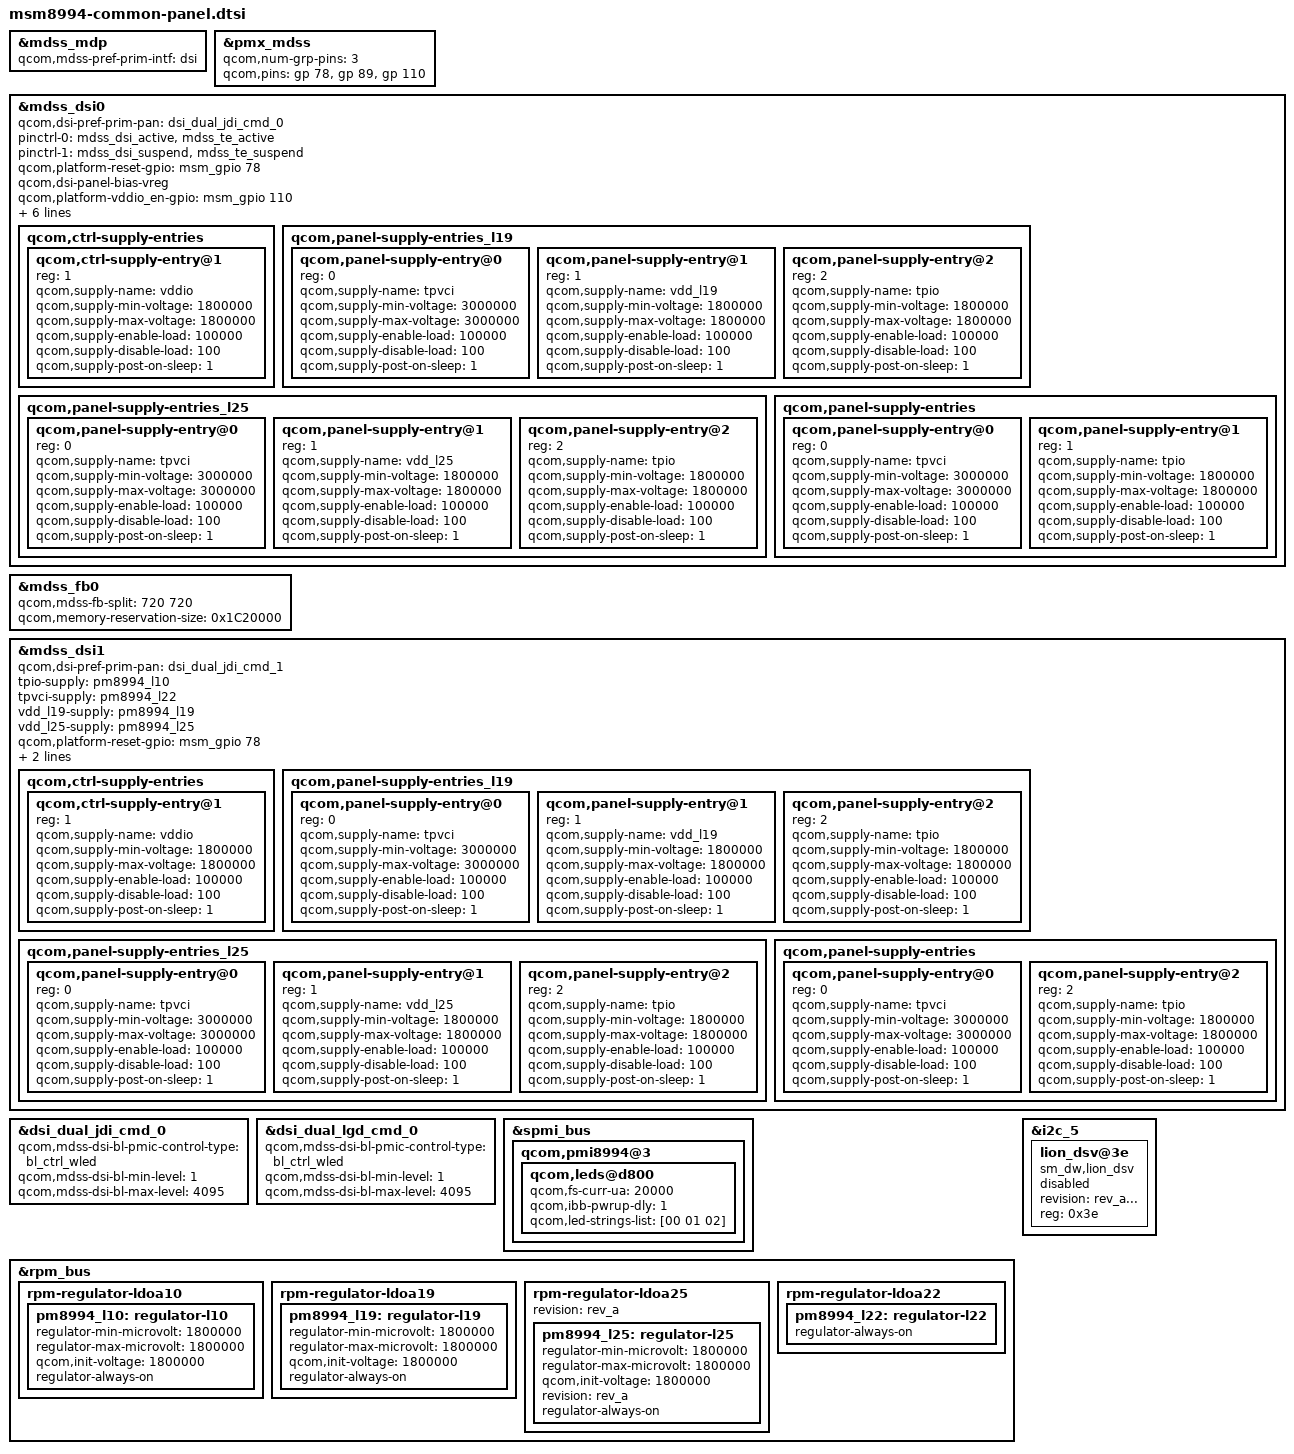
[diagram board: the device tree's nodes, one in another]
/* Copyright (c) 2014, The Linux Foundation. All rights reserved.
 *
 * This program is free software; you can redistribute it and/or modify
 * it under the terms of the GNU General Public License version 2 and
 * only version 2 as published by the Free Software Foundation.
 *
 * This program is distributed in the hope that it will be useful,
 * but WITHOUT ANY WARRANTY; without even the implied warranty of
 * MERCHANTABILITY or FITNESS FOR A PARTICULAR PURPOSE.  See the
 * GNU General Public License for more details.
 */


//copy from msm8994-cdp.dtsi and modify.

#include "dsi-panel-jdi-nt36850-dualmipi0-qhd-cmd.dtsi"
#include "dsi-panel-jdi-nt36850-dualmipi1-qhd-cmd.dtsi"
//#include "dsi-panel-jdi-nt36850-dualmipi0-qhd-video.dtsi"
//#include "dsi-panel-jdi-nt36850-dualmipi1-qhd-video.dtsi"
#include "dsi-panel-lgd-r69007-dualmipi0-qhd-cmd.dtsi"
#include "dsi-panel-lgd-r69007-dualmipi1-qhd-cmd.dtsi"

&mdss_mdp {
	qcom,mdss-pref-prim-intf = "dsi";
	/delete-property/ qcom,mdss-has-source-split;
};

&pmx_mdss {
	qcom,num-grp-pins = <3>;
	qcom,pins = <&gp 78>, <&gp 89>, <&gp 110>;
};

&mdss_dsi0 {
	qcom,dsi-pref-prim-pan = <&dsi_dual_jdi_cmd_0>;
	pinctrl-names = "mdss_default", "mdss_sleep";

	/* pinctrl-0 = <&mdss_dsi_active>; */
	/* pinctrl-1 = <&mdss_dsi_suspend>; */
	/* Add TE pin control status on the PINCTRL structure */
	pinctrl-0 = <&mdss_dsi_active &mdss_te_active>;
	pinctrl-1 = <&mdss_dsi_suspend &mdss_te_suspend>;

	qcom,platform-reset-gpio = <&msm_gpio 78 0>;
	qcom,dsi-panel-bias-vreg;
	qcom,platform-vddio_en-gpio = <&msm_gpio 110 0>;
	qcom,platform-avdd-gpio = <&msm_gpio 89 0>;

	lge,vdd_ldo = < // 1:LDO19 2:LDO25 3:NONE
		1 1  // rev_0 = 1;  rev_a = 1
		3 3  // rev_b = 3;  rev_c = 3
		3 3  // rev_d = 3;  rev_e = 3
		3 3  // rev_f = 3;  rev_g = 3
		3 3  // rev_10 = 3; rev_11 = 3
		3    // rev_12 = 3;
		>;

	tpio-supply = <&pm8994_l10>;
	tpvci-supply =  <&pm8994_l22>;
	vdd_l19-supply = <&pm8994_l19>;
	vdd_l25-supply = <&pm8994_l25>;

	qcom,ctrl-supply-entries {
		qcom,ctrl-supply-entry@1 { //vddio-supply = <&pm8994_l12>;
			reg = <1>;
			qcom,supply-name = "vddio";
			qcom,supply-min-voltage = <1800000>;
			qcom,supply-max-voltage = <1800000>;
			qcom,supply-enable-load = <100000>;
			qcom,supply-disable-load = <100>;
			qcom,supply-post-on-sleep = <1>;
		};
	};

	qcom,panel-supply-entries_l19 {
		#address-cells = <1>;
		#size-cells = <0>;

		qcom,panel-supply-entry@0 {
			reg = <0>;
			qcom,supply-name = "tpvci";
			qcom,supply-min-voltage = <3000000>;
			qcom,supply-max-voltage = <3000000>;
			qcom,supply-enable-load = <100000>;
			qcom,supply-disable-load = <100>;
			qcom,supply-post-on-sleep = <1>;
		};

		qcom,panel-supply-entry@1 {
			reg = <1>;
			qcom,supply-name = "vdd_l19";
			qcom,supply-min-voltage = <1800000>;
			qcom,supply-max-voltage = <1800000>;
			qcom,supply-enable-load = <100000>;
			qcom,supply-disable-load = <100>;
			qcom,supply-post-on-sleep = <1>;
		};

		qcom,panel-supply-entry@2 {
			reg = <2>;
			qcom,supply-name = "tpio";
			qcom,supply-min-voltage = <1800000>;
			qcom,supply-max-voltage = <1800000>;
			qcom,supply-enable-load = <100000>;
			qcom,supply-disable-load = <100>;
			qcom,supply-post-on-sleep = <1>;
		};
	};

	qcom,panel-supply-entries_l25 {
		#address-cells = <1>;
		#size-cells = <0>;

		qcom,panel-supply-entry@0 {
			reg = <0>;
			qcom,supply-name = "tpvci";
			qcom,supply-min-voltage = <3000000>;
			qcom,supply-max-voltage = <3000000>;
			qcom,supply-enable-load = <100000>;
			qcom,supply-disable-load = <100>;
			qcom,supply-post-on-sleep = <1>;
		};

		qcom,panel-supply-entry@1 {
			reg = <1>;
			qcom,supply-name = "vdd_l25";
			qcom,supply-min-voltage = <1800000>;
			qcom,supply-max-voltage = <1800000>;
			qcom,supply-enable-load = <100000>;
			qcom,supply-disable-load = <100>;
			qcom,supply-post-on-sleep = <1>;
		};

		qcom,panel-supply-entry@2 {
			reg = <2>;
			qcom,supply-name = "tpio";
			qcom,supply-min-voltage = <1800000>;
			qcom,supply-max-voltage = <1800000>;
			qcom,supply-enable-load = <100000>;
			qcom,supply-disable-load = <100>;
			qcom,supply-post-on-sleep = <1>;
		};
	};

	qcom,panel-supply-entries {
		#address-cells = <1>;
		#size-cells = <0>;

		qcom,panel-supply-entry@0 {
			reg = <0>;
			qcom,supply-name = "tpvci";
			qcom,supply-min-voltage = <3000000>;
			qcom,supply-max-voltage = <3000000>;
			qcom,supply-enable-load = <100000>;
			qcom,supply-disable-load = <100>;
			qcom,supply-post-on-sleep = <1>;
		};

		qcom,panel-supply-entry@1 {
			reg = <1>;
			qcom,supply-name = "tpio";
			qcom,supply-min-voltage = <1800000>;
			qcom,supply-max-voltage = <1800000>;
			qcom,supply-enable-load = <100000>;
			qcom,supply-disable-load = <100>;
			qcom,supply-post-on-sleep = <1>;
		};
	};
};

&mdss_fb0 {
	qcom,mdss-fb-split = <720 720>;
	qcom,memory-reservation-size = <0x1C20000>;
};

&mdss_dsi1 {
	qcom,dsi-pref-prim-pan = <&dsi_dual_jdi_cmd_1>;

	tpio-supply = <&pm8994_l10>;
	tpvci-supply =  <&pm8994_l22>;
	vdd_l19-supply = <&pm8994_l19>;
	vdd_l25-supply = <&pm8994_l25>;

	qcom,platform-reset-gpio = <&msm_gpio 78 0>;
	lge,reset-low-hold = <10>;

	lge,vdd_ldo = < // 1:LDO19 2:LDO25 3:NONE
		1 1  // rev_0 = 1;  rev_a = 1
		3 3  // rev_b = 3;  rev_c = 3
		3 3  // rev_d = 3;  rev_e = 3
		3 3  // rev_f = 3;  rev_g = 3
		3 3  // rev_10 = 3; rev_11 = 3
		3    // rev_12 = 3;
		>;

	qcom,ctrl-supply-entries {
		qcom,ctrl-supply-entry@1 { //vddio-supply = <&pm8994_l12>;
			reg = <1>;
			qcom,supply-name = "vddio";
			qcom,supply-min-voltage = <1800000>;
			qcom,supply-max-voltage = <1800000>;
			qcom,supply-enable-load = <100000>;
			qcom,supply-disable-load = <100>;
			qcom,supply-post-on-sleep = <1>;
		};
	};

	qcom,panel-supply-entries_l19 {
		#address-cells = <1>;
		#size-cells = <0>;

		qcom,panel-supply-entry@0 {
			reg = <0>;
			qcom,supply-name = "tpvci";
			qcom,supply-min-voltage = <3000000>;
			qcom,supply-max-voltage = <3000000>;
			qcom,supply-enable-load = <100000>;
			qcom,supply-disable-load = <100>;
			qcom,supply-post-on-sleep = <1>;
		};

		qcom,panel-supply-entry@1 {
			reg = <1>;
			qcom,supply-name = "vdd_l19";
			qcom,supply-min-voltage = <1800000>;
			qcom,supply-max-voltage = <1800000>;
			qcom,supply-enable-load = <100000>;
			qcom,supply-disable-load = <100>;
			qcom,supply-post-on-sleep = <1>;
		};

		qcom,panel-supply-entry@2 {
			reg = <2>;
			qcom,supply-name = "tpio";
			qcom,supply-min-voltage = <1800000>;
			qcom,supply-max-voltage = <1800000>;
			qcom,supply-enable-load = <100000>;
			qcom,supply-disable-load = <100>;
			qcom,supply-post-on-sleep = <1>;
		};
	};

	qcom,panel-supply-entries_l25 {
		#address-cells = <1>;
		#size-cells = <0>;

		qcom,panel-supply-entry@0 {
			reg = <0>;
			qcom,supply-name = "tpvci";
			qcom,supply-min-voltage = <3000000>;
			qcom,supply-max-voltage = <3000000>;
			qcom,supply-enable-load = <100000>;
			qcom,supply-disable-load = <100>;
			qcom,supply-post-on-sleep = <1>;
		};

		qcom,panel-supply-entry@1 {
			reg = <1>;
			qcom,supply-name = "vdd_l25";
			qcom,supply-min-voltage = <1800000>;
			qcom,supply-max-voltage = <1800000>;
			qcom,supply-enable-load = <100000>;
			qcom,supply-disable-load = <100>;
			qcom,supply-post-on-sleep = <1>;
		};

		qcom,panel-supply-entry@2 {
			reg = <2>;
			qcom,supply-name = "tpio";
			qcom,supply-min-voltage = <1800000>;
			qcom,supply-max-voltage = <1800000>;
			qcom,supply-enable-load = <100000>;
			qcom,supply-disable-load = <100>;
			qcom,supply-post-on-sleep = <1>;
		};
	};

	qcom,panel-supply-entries {
		#address-cells = <1>;
		#size-cells = <0>;

		qcom,panel-supply-entry@0 {
			reg = <0>;
			qcom,supply-name = "tpvci";
			qcom,supply-min-voltage = <3000000>;
			qcom,supply-max-voltage = <3000000>;
			qcom,supply-enable-load = <100000>;
			qcom,supply-disable-load = <100>;
			qcom,supply-post-on-sleep = <1>;
		};

		qcom,panel-supply-entry@2 {
			reg = <2>;
			qcom,supply-name = "tpio";
			qcom,supply-min-voltage = <1800000>;
			qcom,supply-max-voltage = <1800000>;
			qcom,supply-enable-load = <100000>;
			qcom,supply-disable-load = <100>;
			qcom,supply-post-on-sleep = <1>;
		};
	};
};

&dsi_dual_jdi_cmd_0{
	qcom,mdss-dsi-bl-pmic-control-type = "bl_ctrl_wled";
	qcom,mdss-dsi-bl-min-level = <1>;
	qcom,mdss-dsi-bl-max-level = <4095>;
};

&dsi_dual_lgd_cmd_0{
	qcom,mdss-dsi-bl-pmic-control-type = "bl_ctrl_wled";
	qcom,mdss-dsi-bl-min-level = <1>;
	qcom,mdss-dsi-bl-max-level = <4095>;
};

&spmi_bus {
	qcom,pmi8994@3 {
		qcom,leds@d800 {
			qcom,fs-curr-ua = <20000>;
			qcom,ibb-pwrup-dly = <1>;
			qcom,led-strings-list = [00 01 02];
		};
	};
};

/* RPM controlled regulators: */

&rpm_bus {
	rpm-regulator-ldoa10 {
		status = "okay";
		pm8994_l10: regulator-l10 {
			regulator-min-microvolt = <1800000>;
			regulator-max-microvolt = <1800000>;
			qcom,init-voltage = <1800000>;
			status = "okay";
			regulator-always-on;
		};

	};
	rpm-regulator-ldoa19 {
		status = "okay";
		pm8994_l19: regulator-l19 {
			regulator-min-microvolt = <1800000>;
			regulator-max-microvolt = <1800000>;
			qcom,init-voltage = <1800000>;
			status = "okay";
			regulator-always-on;
		};
	};
	rpm-regulator-ldoa25 {
		status = "okay";
		revision = "rev_a";
		pm8994_l25: regulator-l25 {
			regulator-min-microvolt = <1800000>;
			regulator-max-microvolt = <1800000>;
			qcom,init-voltage = <1800000>;
			status = "okay";
			revision = "rev_a";
			regulator-always-on;
		};
	};
	rpm-regulator-ldoa22 {
		status = "okay";
		pm8994_l22: regulator-l22 {
			regulator-always-on;
		};
	};
};
&i2c_5 {
    lion_dsv@3e {
        status = "disable";
        revision = "rev_a...";
        compatible = "sm_dw,lion_dsv";
        reg = <0x3e>;
    };
};
